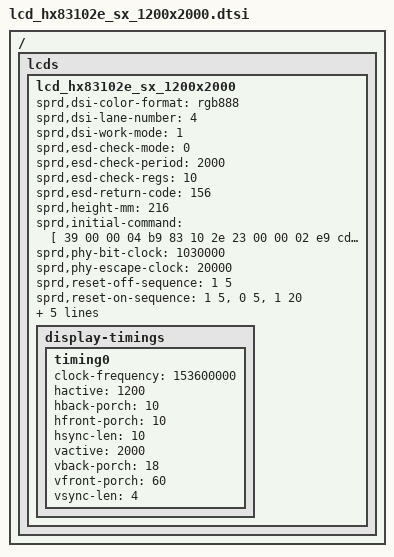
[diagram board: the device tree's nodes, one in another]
/ { lcds {
		lcd_hx83102e_sx_1200x2000: lcd_hx83102e_sx_1200x2000 {

				sprd,dsi-color-format = "rgb888";
				sprd,dsi-lane-number = <4>;
				sprd,dsi-work-mode = <1>;

				sprd,esd-check-mode = <0>;
				sprd,esd-check-period = <2000>;
				sprd,esd-check-regs = <10>;
				sprd,esd-return-code = <156>;

				sprd,height-mm = <216>;

				sprd,initial-command = [
						39 00 00 04 b9 83
						10 2e 23 00 00 02
						e9 cd 23 00 00 02
						bb 01 23 00 00 02
						e9 00 39 00 00 09
						ba 70 03 a8 83 f2
						80 00 0d 39 00 00
						03 51 0f ff 23 00
						00 02 53 24 39 00
						00 04 c9 04 0b 5d
						39 00 00 04 ce 00
						50 f0 39 00 00 03
						d2 e8 e8 39 00 00
						04 d9 04 01 02 39
						00 00 2d d5 03 02
						01 00 07 06 05 04
						18 18 24 24 19 19
						18 18 19 19 21 20
						23 22 18 18 18 18
						18 18 18 18 18 18
						18 18 18 18 18 18
						18 18 18 18 18 18
						39 00 00 2d d6 04
						05 06 07 00 01 02
						03 18 18 24 24 19
						19 19 19 18 18 22
						23 20 21 18 18 18
						18 18 18 18 18 18
						18 18 18 18 18 18
						18 18 18 18 18 18
						18 39 00 00 11 b4
						80 60 01 01 80 60
						68 50 01 8e 01 58
						00 ff 00 ff 39 00
						00 2b d3 00 00 00
						00 01 04 00 08 08
						27 27 22 2f 23 23
						04 04 32 10 21 00
						21 32 10 1f 00 02
						32 17 fd 00 10 00
						00 20 30 01 55 21
						38 01 55 39 00 00
						05 d1 67 0c ff 05
						39 00 00 12 b1 10
						fa af af 29 2d b2
						57 4d 30 30 36 36
						22 21 15 00 39 00
						00 09 b2 00 b0 47
						d0 00 14 3c 2e 39
						00 00 2f e0 00 01
						0a 11 19 2b 44 4c
						55 53 71 76 7d 8c
						89 91 9a ad ac 56
						5e 68 73 00 09 12
						19 1f 37 4e 54 5b
						57 6f 74 79 86 83
						89 90 a3 a2 50 58
						64 73 39 00 00 0f
						c0 27 27 44 11 a2
						17 00 86 00 00 00
						00 63 63 23 00 00
						02 cc 02 39 00 00
						07 c8 00 04 04 00
						00 82 39 00 00 08
						bf fc 85 80 9c 36
						00 1c 39 00 00 04
						d0 07 04 05 23 00
						00 02 bd 01 39 00
						00 0a d3 01 00 fc
						00 00 11 10 00 0e
						23 00 00 02 bd 02
						23 00 00 02 b4 4e
						23 00 00 02 bf f2
						39 00 00 0d d8 ff
						ff ff ff ff f0 ff
						ff ff ff ff f0 23
						00 00 02 bd 00 39
						00 00 17 e7 12 13
						02 02 2b 00 0e 0e
						00 02 27 76 1e 76
						01 27 00 00 00 00
						17 00 23 00 00 02
						bd 01 39 00 00 08
						e7 02 30 01 94 0d
						b8 0e 23 00 00 02
						bd 02 39 00 00 1d
						e7 ff 01 fd 01 00
						00 22 00 00 00 00
						00 00 00 00 00 00
						00 00 00 00 00 00
						00 81 00 02 40 23
						00 00 02 bd 00 23
						00 00 02 55 01 39
						00 00 19 e4 25 41
						2c 33 4c 66 81 99
						b2 cc e5 ff ff ff
						03 1e 1e 1e 1e 00
						00 05 01 14 23 00
						00 02 bd 01 39 00
						00 28 e4 e1 e1 e1
						e1 e1 e1 e1 e1 c7
						b2 a0 90 81 75 69
						5f 55 4c 44 3d 36
						2f 2a 24 1e 19 14
						10 0d 0b 09 54 55
						55 55 55 55 55 55
						23 00 00 02 bd 00
						23 00 00 02 c1 01
						23 00 00 02 bd 01
						39 00 00 3b c1 01
						04 08 0c 10 14 18
						1c 20 24 27 2c 30
						34 38 3c 40 44 48
						4c 54 5c 63 6b 73
						7b 83 8a 92 9a a2
						aa b3 ba c1 ca d1
						d9 e1 e9 f1 f5 f7
						f8 fa fc 00 40 4c
						0b e4 5f f7 f5 08
						95 03 c0 23 00 00
						02 bd 02 39 00 00
						3b c1 00 04 08 0c
						10 14 18 1c 20 24
						28 2c 30 34 39 3d
						41 45 48 4c 55 5c
						64 6c 74 7c 84 8b
						93 9b a3 ab b4 bb
						c3 cb d3 db e3 eb
						f3 f7 f9 fb fe ff
						01 45 92 a1 5f 3b
						f7 fb 13 9b ff 00
						23 00 00 02 bd 03
						39 00 00 3b c1 00
						04 08 0c 10 14 18
						1c 20 24 28 2d 31
						35 3a 3e 42 46 49
						4e 56 5e 66 6e 76
						7e 85 8d 95 9d a4
						ac b5 bc c4 cc d4
						db e4 ec f3 f7 f9
						fc fe ff 15 9a fc
						21 5c 40 18 0b 01
						30 fc 00 23 00 00
						02 bd 00 39 00 00
						03 e1 07 00 39 00
						00 04 b9 00 00 00
						13 78 00 01 11 13
						64 00 01 29
						];

				sprd,phy-bit-clock = <1030000>;
				sprd,phy-escape-clock = <20000>;

				sprd,reset-off-sequence = <1 5>;
				sprd,reset-on-sequence = <1 5>, <0 5>, <1 20>;

				sprd,sleep-in-command = <319422465 672364544 17834752 151297>;
				sprd,sleep-out-command = [
						13 78 00 01 11 13
						64 00 01 29
						];

				sprd,width-mm = <135>;

				display-timings {
						timing0 {
								clock-frequency = <153600000>;
								hactive = <1200>;
								hback-porch = <10>;
								hfront-porch = <10>;
								hsync-len = <10>;
								vactive = <2000>;
								vback-porch = <18>;
								vfront-porch = <60>;
								vsync-len = <4>;
						};
				};
		};
}; };
